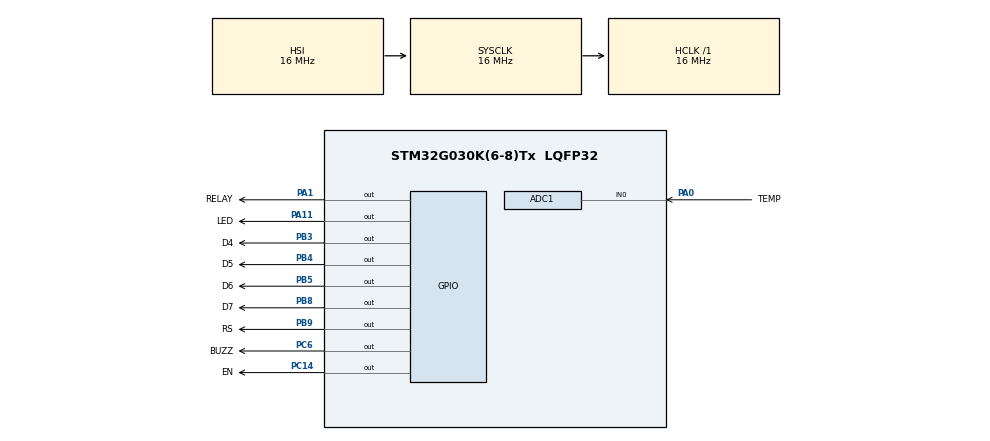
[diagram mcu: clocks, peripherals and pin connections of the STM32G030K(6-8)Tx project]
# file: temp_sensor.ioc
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ADC1.Channel-0\#ChannelRegularConversion=ADC_CHANNEL_0
ADC1.NbrOfConversionFlag=1
ADC1.Rank-0\#ChannelRegularConversion=1
ADC1.SamplingTime-0\#ChannelRegularConversion=ADC_SAMPLINGTIME_COMMON_1
ADC1.SelectedChannel=ADC_CHANNEL_0
ADC1.master=1
Mcu.Family=STM32G0
Mcu.Name=STM32G030K(6-8)Tx
Mcu.Package=LQFP32
PA0.GPIO_Label=TEMP
PA0.Mode=IN0
PA0.Signal=ADC1_IN0
PA1.GPIO_Label=RELAY
PA1.Signal=GPIO_Output
PA11\ [PA9].GPIO_Label=LED
PA11\ [PA9].Signal=GPIO_Output
PB3.GPIO_Label=D4
PB3.Signal=GPIO_Output
PB4.GPIO_Label=D5
PB4.Signal=GPIO_Output
PB5.GPIO_Label=D6
PB5.Signal=GPIO_Output
PB8.GPIO_Label=D7
PB8.Signal=GPIO_Output
PB9.GPIO_Label=RS
PB9.Signal=GPIO_Output
PC14-OSC32_IN\ (PC14).GPIO_Label=EN
PC14-OSC32_IN\ (PC14).Signal=GPIO_Output
PC6.GPIO_Label=BUZZ
PC6.Signal=GPIO_Output
ProjectManager.HeapSize=0x200
ProjectManager.StackSize=0x400
ProjectManager.TargetToolchain=STM32CubeIDE
RCC.AHBFreq_Value=16000000
RCC.CortexFreq_Value=16000000
RCC.EXTERNAL_CLOCK_VALUE=12288000
RCC.HCLKFreq_Value=16000000
RCC.HSE_VALUE=8000000
RCC.HSI_VALUE=16000000
RCC.LSE_VALUE=32768
RCC.SYSCLKFreq_VALUE=16000000
RCC.VCOOutputFreq_Value=128000000
board=custom

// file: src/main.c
/* USER CODE BEGIN Header */
/**
  ******************************************************************************
  * @file           : main.c
  * @brief          : Main program body
  ******************************************************************************
  * @attention
  *
  * Copyright (c) 2024 STMicroelectronics.
  * All rights reserved.
  *
  * This software is licensed under terms that can be found in the LICENSE file
  * in the root directory of this software component.
  * If no LICENSE file comes with this software, it is provided AS-IS.
  *
  ******************************************************************************
  */
/* USER CODE END Header */
#include "main.h"
#include "LCD1602.h"
#include  <stdio.h>

/* USER CODE BEGIN PTD */
#define VREF 3.3
#define THRESHOLD_TEMP 28.0
/* USER CODE END PTD */

/* USER CODE BEGIN PD */
float Threshold_value;
uint32_t temp_sensor;
float temp;
/* USER CODE END PD */

ADC_HandleTypeDef hadc1;

void SystemClock_Config(void);
static void MX_GPIO_Init(void);
static void MX_ADC1_Init(void);

int main(void)
{

  /* MCU Configuration--------------------------------------------------------*/

  /* Reset of all peripherals, Initializes the Flash interface and the Systick. */
  HAL_Init();

  /* Configure the system clock */
  SystemClock_Config();

  /* Initialize all configured peripherals */
  MX_GPIO_Init();
  MX_ADC1_Init();
  lcd_init();
  /* USER CODE BEGIN 2 */
  	  	HAL_ADC_Start(&hadc1);

  /* USER CODE END 2 */

  /* Infinite loop */
  /* USER CODE BEGIN WHILE */
  while (1)
  {
	  HAL_ADC_PollForConversion(&hadc1, HAL_MAX_DELAY) == HAL_OK;
	  	  	      	temp_sensor = HAL_ADC_GetValue(&hadc1);
	  	  	      	temp = ((temp_sensor * VREF) / 4096.0) * 100.0;

	  	  	      		  LCDClear();
	  	  	      		  lcd_put_cur(0,1);
	  	  	      		  char temp_str[16];
	  	  	      		        snprintf(temp_str, sizeof(temp_str), "Temp: %.2fC", temp);
	  	  	      		          LCDSendString(temp_str);
	  	  	      		          HAL_Delay(500);

	  	  	      		      if (temp > THRESHOLD_TEMP)
	  	  	      		                  {
	  	  	      		                      // Turn on LED and Buzzer
	  	  	      		                        // Turn on LED
	  	  	      		                      HAL_GPIO_WritePin(BUZZ_GPIO_Port,BUZZ_Pin, GPIO_PIN_SET); // Turn on Buzzer
	  	  	      		                      HAL_GPIO_WritePin(LED_GPIO_Port,LED_Pin, GPIO_PIN_SET);
	  	  	      		                      HAL_GPIO_WritePin(RELAY_GPIO_Port, RELAY_Pin, GPIO_PIN_SET);
	  	  	      		                      // Delay for 2 seconds
	  	  	      		                      HAL_Delay(2000);

	  	  	      		                      // Turn off LED and Buzzer
	  	  	      		                       // Turn off LED
	  	  	      		                      HAL_GPIO_WritePin(BUZZ_GPIO_Port,BUZZ_Pin, GPIO_PIN_RESET);
	  	  	      		                      HAL_GPIO_WritePin(LED_GPIO_Port, LED_Pin, GPIO_PIN_RESET);

	  	  	      		                  }

	  	  	      		                else
	  	  	      		                {
	  	  	      		                    lcd_put_cur(1, 0);        // Set cursor to line 1, position 0
	  	  	      		                    LCDSendString("normal");  // Display "normal" on the LCD
	  	  	      		                }

  }
}

void SystemClock_Config(void)
{
  RCC_OscInitTypeDef RCC_OscInitStruct = {0};
  RCC_ClkInitTypeDef RCC_ClkInitStruct = {0};

  /** Configure the main internal regulator output voltage
  */
  HAL_PWREx_ControlVoltageScaling(PWR_REGULATOR_VOLTAGE_SCALE1);

  /** Initializes the RCC Oscillators according to the specified parameters
  * in the RCC_OscInitTypeDef structure.
  */
  RCC_OscInitStruct.OscillatorType = RCC_OSCILLATORTYPE_HSI;
  RCC_OscInitStruct.HSIState = RCC_HSI_ON;
  RCC_OscInitStruct.HSIDiv = RCC_HSI_DIV1;
  RCC_OscInitStruct.HSICalibrationValue = RCC_HSICALIBRATION_DEFAULT;
  RCC_OscInitStruct.PLL.PLLState = RCC_PLL_NONE;
  if (HAL_RCC_OscConfig(&RCC_OscInitStruct) != HAL_OK)
  {
    Error_Handler();
  }

  /** Initializes the CPU, AHB and APB buses clocks
  */
  RCC_ClkInitStruct.ClockType = RCC_CLOCKTYPE_HCLK|RCC_CLOCKTYPE_SYSCLK
                              |RCC_CLOCKTYPE_PCLK1;
  RCC_ClkInitStruct.SYSCLKSource = RCC_SYSCLKSOURCE_HSI;
  RCC_ClkInitStruct.AHBCLKDivider = RCC_SYSCLK_DIV1;
  RCC_ClkInitStruct.APB1CLKDivider = RCC_HCLK_DIV1;

  if (HAL_RCC_ClockConfig(&RCC_ClkInitStruct, FLASH_LATENCY_0) != HAL_OK)
  {
    Error_Handler();
  }
}

static void MX_ADC1_Init(void)
{

  ADC_ChannelConfTypeDef sConfig = {0};

  /** Configure the global features of the ADC (Clock, Resolution, Data Alignment and number of conversion)
  */
  hadc1.Instance = ADC1;
  hadc1.Init.ClockPrescaler = ADC_CLOCK_SYNC_PCLK_DIV2;
  hadc1.Init.Resolution = ADC_RESOLUTION_12B;
  hadc1.Init.DataAlign = ADC_DATAALIGN_RIGHT;
  hadc1.Init.ScanConvMode = ADC_SCAN_DISABLE;
  hadc1.Init.EOCSelection = ADC_EOC_SINGLE_CONV;
  hadc1.Init.LowPowerAutoWait = DISABLE;
  hadc1.Init.LowPowerAutoPowerOff = DISABLE;
  hadc1.Init.ContinuousConvMode = DISABLE;
  hadc1.Init.NbrOfConversion = 1;
  hadc1.Init.DiscontinuousConvMode = DISABLE;
  hadc1.Init.ExternalTrigConv = ADC_SOFTWARE_START;
  hadc1.Init.ExternalTrigConvEdge = ADC_EXTERNALTRIGCONVEDGE_NONE;
  hadc1.Init.DMAContinuousRequests = DISABLE;
  hadc1.Init.Overrun = ADC_OVR_DATA_PRESERVED;
  hadc1.Init.SamplingTimeCommon1 = ADC_SAMPLETIME_1CYCLE_5;
  hadc1.Init.SamplingTimeCommon2 = ADC_SAMPLETIME_1CYCLE_5;
  hadc1.Init.OversamplingMode = DISABLE;
  hadc1.Init.TriggerFrequencyMode = ADC_TRIGGER_FREQ_HIGH;
  if (HAL_ADC_Init(&hadc1) != HAL_OK)
  {
    Error_Handler();
  }

  /** Configure Regular Channel
  */
  sConfig.Channel = ADC_CHANNEL_0;
  sConfig.Rank = ADC_REGULAR_RANK_1;
  sConfig.SamplingTime = ADC_SAMPLINGTIME_COMMON_1;
  if (HAL_ADC_ConfigChannel(&hadc1, &sConfig) != HAL_OK)
  {
    Error_Handler();
  }

}

static void MX_GPIO_Init(void)
{
  GPIO_InitTypeDef GPIO_InitStruct = {0};

  /* GPIO Ports Clock Enable */
  __HAL_RCC_GPIOB_CLK_ENABLE();
  __HAL_RCC_GPIOC_CLK_ENABLE();
  __HAL_RCC_GPIOA_CLK_ENABLE();

  /*Configure GPIO pin Output Level */
  HAL_GPIO_WritePin(GPIOB, RS_Pin|D4_Pin|D5_Pin|D6_Pin
                          |D7_Pin, GPIO_PIN_RESET);

  /*Configure GPIO pin Output Level */
  HAL_GPIO_WritePin(GPIOC, EN_Pin|BUZZ_Pin, GPIO_PIN_RESET);

  /*Configure GPIO pin Output Level */
  HAL_GPIO_WritePin(GPIOA, RELAY_Pin|LED_Pin, GPIO_PIN_RESET);

  /*Configure GPIO pins : RS_Pin D4_Pin D5_Pin D6_Pin
                           D7_Pin */
  GPIO_InitStruct.Pin = RS_Pin|D4_Pin|D5_Pin|D6_Pin
                          |D7_Pin;
  GPIO_InitStruct.Mode = GPIO_MODE_OUTPUT_PP;
  GPIO_InitStruct.Pull = GPIO_NOPULL;
  GPIO_InitStruct.Speed = GPIO_SPEED_FREQ_LOW;
  HAL_GPIO_Init(GPIOB, &GPIO_InitStruct);

  /*Configure GPIO pins : EN_Pin BUZZ_Pin */
  GPIO_InitStruct.Pin = EN_Pin|BUZZ_Pin;
  GPIO_InitStruct.Mode = GPIO_MODE_OUTPUT_PP;
  GPIO_InitStruct.Pull = GPIO_NOPULL;
  GPIO_InitStruct.Speed = GPIO_SPEED_FREQ_LOW;
  HAL_GPIO_Init(GPIOC, &GPIO_InitStruct);

  /*Configure GPIO pins : RELAY_Pin LED_Pin */
  GPIO_InitStruct.Pin = RELAY_Pin|LED_Pin;
  GPIO_InitStruct.Mode = GPIO_MODE_OUTPUT_PP;
  GPIO_InitStruct.Pull = GPIO_NOPULL;
  GPIO_InitStruct.Speed = GPIO_SPEED_FREQ_LOW;
  HAL_GPIO_Init(GPIOA, &GPIO_InitStruct);

}

void Error_Handler(void)
{
  __disable_irq();
  while (1)
  {
  }
}
